AUTOSAR XML (schema 4-2-2)
package /AUTOLIV/SoftwareComponents/BSR
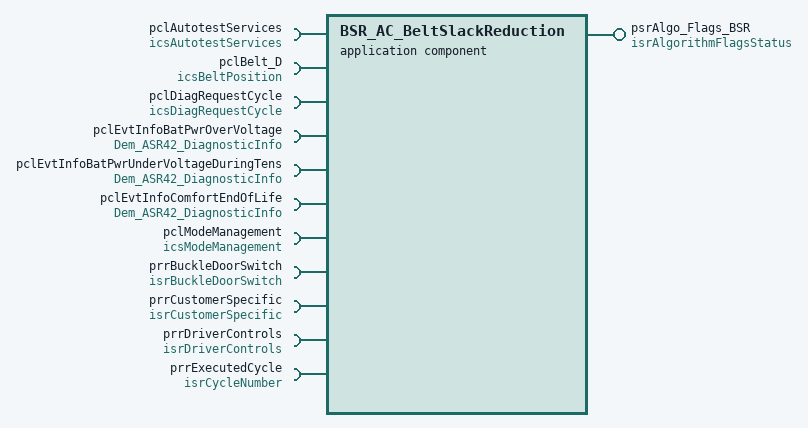
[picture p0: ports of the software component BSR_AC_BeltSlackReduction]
  application sw component type BSR_AC_BeltSlackReduction: category=SWC
    11 x require port:
      pclAutotestServices: required-com-specs=[GetTestResult, GetLastCriticalAutotestID], required-interface=icsAutotestServices
      pclBelt_D: required-com-specs=[GetFromT0_mm, GetFromT0_deg, GetRange_mm, GetRange_deg, GetFromMinPos_deg, GetFromMinPos_mm], required-interface=icsBeltPosition
      pclDiagRequestCycle: required-com-specs=[GetDiagRequestCycle, ClearDiagRequestCycle], required-interface=icsDiagRequestCycle
      pclEvtInfoBatPwrOverVoltage: required-interface=Dem_ASR42_DiagnosticInfo
        required-com-specs:
          GetEventStatus
          GetEventFailed
          GetEventTested
          GetDTCOfEvent
          GetFaultDetectionCounter
          GetEventFreezeFrameData
          GetEventExtendedDataRecord
      pclEvtInfoBatPwrUnderVoltageDuringTens: required-interface=Dem_ASR42_DiagnosticInfo
        required-com-specs:
          GetEventStatus
          GetEventFailed
          GetEventTested
          GetDTCOfEvent
          GetFaultDetectionCounter
          GetEventFreezeFrameData
          GetEventExtendedDataRecord
      pclEvtInfoComfortEndOfLife: required-interface=Dem_ASR42_DiagnosticInfo
        required-com-specs:
          GetEventStatus
          GetEventFailed
          GetEventTested
          GetDTCOfEvent
          GetFaultDetectionCounter
          GetEventFreezeFrameData
          GetEventExtendedDataRecord
      pclModeManagement: client-com-spec=CheckModeStatus, required-interface=icsModeManagement
      prrBuckleDoorSwitch: required-interface=isrBuckleDoorSwitch
        required-com-specs:
          data-element=u8BuckleSwitch, uses-end-to-end-protection=0, init-value=constant-reference=APPLINIT_KU8_BUCKLE_SWITCH_STATUS_NOT_DEFINED
          data-element=u8DoorSwitch, uses-end-to-end-protection=0, init-value=constant-reference=APPLINIT_KU8_DOOR_SWITCH_STATUS_NOT_DEFINED
      prrCustomerSpecific: required-interface=isrCustomerSpecific
        required-com-specs:
          data-element=b8IsCarCrashDetected, uses-end-to-end-protection=0, init-value=constant-reference=APPLINIT_KB8_CAR_CRASH_DETECTED_FALSE
          data-element=b8IsCarCrankingActive, uses-end-to-end-protection=0, init-value=constant-reference=APPLINIT_KB8_CAR_CRANKING_ACTIVE_TRUE
          data-element=u8BeltSlackStatus, uses-end-to-end-protection=0, init-value=constant-reference=APPLINIT_KU8_BELT_SLACK_STATUS_NOT_DEFINED
          data-element=u8PreCrashRequest, uses-end-to-end-protection=0, init-value=constant-reference=APPLINIT_KU8_PRE_CRASH_REQUEST_NO_REQUEST
          data-element=b8PreCrashRequestEnable, uses-end-to-end-protection=0, init-value=constant-reference=APPLINIT_KB8_BOOLEAN_FALSE
          data-element=u8HapticRequest, uses-end-to-end-protection=0, init-value=constant-reference=APPLINIT_KU8_HAPTIC_REQUEST_NO
      prrDriverControls: required-interface=isrDriverControls
        required-com-specs:
          data-element=u16VehicleSpeed, uses-end-to-end-protection=0, init-value=constant-reference=APPLINIT_KU16_VEHICLE_SPEED_ZERO
          data-element=u16BrakePressure, uses-end-to-end-protection=0, init-value=constant-reference=APPLINIT_KU16_BRAKE_PRESSURE_ZERO
          data-element=s16BrakePressureRate, uses-end-to-end-protection=0, init-value=constant-reference=APPLINIT_KS16_BRAKE_PRESSURE_RATE_ZERO
          data-element=u8AccelerationPedalPosition, uses-end-to-end-protection=0, init-value=constant-reference=APPLINIT_KU8_ACCEL_PEDAL_POS_ZERO
          data-element=s16AccelerationPedalPositionRate, uses-end-to-end-protection=0, init-value=constant-reference=APPLINIT_KS16_ACCEL_PEDAL_POS_RATE_ZERO
          data-element=s16HWAngle, uses-end-to-end-protection=0, init-value=constant-reference=APPLINIT_KS16_HW_ANGLE_ZERO
          data-element=s16HWRate, uses-end-to-end-protection=0, init-value=constant-reference=APPLINIT_KS16_HW_RATE_ZERO
          data-element=b8VehicleMovingBackwards, uses-end-to-end-protection=0, init-value=constant-reference=APPLINIT_KB8_BOOLEAN_FALSE
          data-element=u8KlemmenStatus, uses-end-to-end-protection=0, init-value=constant-reference=APPLINIT_KU8_KLEMMEN_STATUS_ZERO
      prrExecutedCycle: nonqueued-receiver-com-spec{data-element=u8CycleNumber, uses-end-to-end-protection=0, init-value=constant-reference=APPLINIT_KU8_CYCLE_NUMBER_NONE}, required-interface=isrCycleNumber
    provide port psrAlgo_Flags_BSR: provided-interface=isrAlgorithmFlagsStatus
      provided-com-specs:
        data-element=b8TriggerFlag, uses-end-to-end-protection=0, init-value=constant-reference=APPLINIT_KB8_ALGO_FLAG_FALSE
        data-element=b8InterruptFlag, uses-end-to-end-protection=0, init-value=constant-reference=APPLINIT_KB8_ALGO_FLAG_FALSE
        data-element=b8PreActivationFlag, uses-end-to-end-protection=0, init-value=constant-reference=APPLINIT_KB8_ALGO_FLAG_FALSE
        data-element=b8PreConditionsFlag, uses-end-to-end-protection=0, init-value=constant-reference=APPLINIT_KB8_ALGO_FLAG_FALSE
        data-element=u8TriggeringSource, uses-end-to-end-protection=0, init-value=constant-reference=APPLINIT_KU8_TRIGGERING_SOURCE_NO
